# ESP32-C3 register map
Vendor: ESPRESSIF SYSTEMS (SHANGHAI) CO., LTD.; Series: ESP32 C-Series; File version: 18
CPU: RV32IMC r0p0, little endian, no MPU, no FPU, 0 interrupt priority bits
Address unit: 32 bits
Registers are 32-bit, read-write, reset 0x0 unless marked. A register's access mark holds for its fields unless they carry their own. Offsets are from the block's base; [hi:lo] are bit positions; {n}, {i} and the like mark numbered series.

## TWAI0 — Two-Wire Automotive Interface
Base 0x6002B000
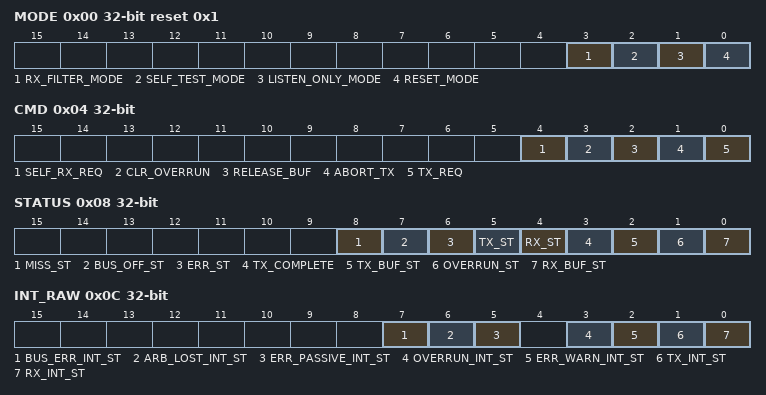
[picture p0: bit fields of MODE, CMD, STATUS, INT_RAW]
0x00 MODE reset 0x1
  [3] RX_FILTER_MODE — This bit is used to configure the filter mode. 0: Dual filter mode; 1: Single filter mode.
  [2] SELF_TEST_MODE — 1: Self test mode. In this mode the TX nodes can perform a successful transmission without receiving the acknowledge signal. This mode is often used to test a single node with the self reception request command.
  [1] LISTEN_ONLY_MODE — 1: Listen only mode. In this mode the nodes will only receive messages from the bus, without generating the acknowledge signal nor updating the RX error counter.
  [0] RESET_MODE — This bit is used to configure the operating mode of the TWAI Controller. 1: Reset mode; 0: Operating mode.
0x04 CMD wo — Command Register
  [4] SELF_RX_REQ — Self reception request command. Set the bit to 1 to allow a message be transmitted and received simultaneously.
  [3] CLR_OVERRUN — Set the bit to 1 to clear the data overrun status bit.
  [2] RELEASE_BUF — Set the bit to 1 to release the RX buffer.
  [1] ABORT_TX — Set the bit to 1 to cancel a pending transmission request.
  [0] TX_REQ — Set the bit to 1 to allow the driving nodes start transmission.
0x08 STATUS ro
  [8] MISS_ST — This bit reflects whether the data packet in the RX FIFO is complete. 1: The current packet is missing; 0: The current packet is complete
  [7] BUS_OFF_ST — 1: In bus-off status, the TWAI Controller is no longer involved in bus activities.
  [6] ERR_ST — 1: At least one of the RX/TX error counter has reached or exceeded the value set in register TWAI_ERR_WARNING_LIMIT_REG.
  [5] TX_ST — 1: The TWAI Controller is transmitting a message to the bus.
  [4] RX_ST — 1: The TWAI Controller is receiving a message from the bus.
  [3] TX_COMPLETE — 1: The TWAI controller has successfully received a packet from the bus.
  [2] TX_BUF_ST — 1: The TX buffer is empty, the CPU may write a message into it.
  [1] OVERRUN_ST — 1: The RX FIFO is full and data overrun has occurred.
  [0] RX_BUF_ST — 1: The data in the RX buffer is not empty, with at least one received data packet.
0x0C INT_RAW ro — Interrupt Register
  [7] BUS_ERR_INT_ST — Error interrupt. If this bit is set to 1, it indicates an error is detected on the bus.
  [6] ARB_LOST_INT_ST — Arbitration lost interrupt. If this bit is set to 1, it indicates an arbitration lost interrupt is generated.
  [5] ERR_PASSIVE_INT_ST — Error passive interrupt. If this bit is set to 1, it indicates the TWAI Controller is switched between error active status and error passive status due to the change of error counters.
  [3] OVERRUN_INT_ST — Data overrun interrupt. If this bit is set to 1, it indicates a data overrun interrupt is generated in the RX FIFO.
  [2] ERR_WARN_INT_ST — Error warning interrupt. If this bit is set to 1, it indicates the error status signal and the bus-off status signal of Status register have changed (e.g., switched from 0 to 1 or from 1 to 0).
  [1] TX_INT_ST — Transmit interrupt. If this bit is set to 1, it indicates the message transmitting mis- sion is finished and a new transmission is able to execute.
  [0] RX_INT_ST — Receive interrupt. If this bit is set to 1, it indicates there are messages to be handled in the RX FIFO.
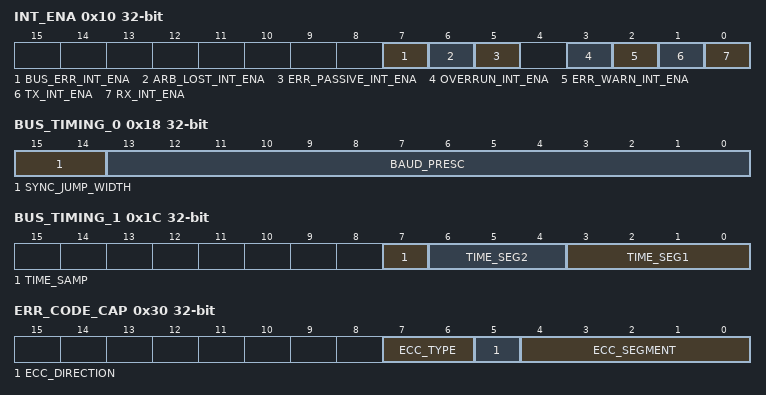
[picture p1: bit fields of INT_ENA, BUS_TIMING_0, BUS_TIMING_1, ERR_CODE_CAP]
0x10 INT_ENA — Interrupt Enable Register
  [7] BUS_ERR_INT_ENA — Set this bit to 1 to enable error interrupt.
  [6] ARB_LOST_INT_ENA — Set this bit to 1 to enable arbitration lost interrupt.
  [5] ERR_PASSIVE_INT_ENA — Set this bit to 1 to enable error passive interrupt.
  [3] OVERRUN_INT_ENA — Set this bit to 1 to enable data overrun interrupt.
  [2] ERR_WARN_INT_ENA — Set this bit to 1 to enable error warning interrupt.
  [1] TX_INT_ENA — Set this bit to 1 to enable transmit interrupt.
  [0] RX_INT_ENA — Set this bit to 1 to enable receive interrupt.
0x18 BUS_TIMING_0 — Bus Timing Register 0
  [15:14] SYNC_JUMP_WIDTH — Synchronization Jump Width (SJW), 1 \verb+~+ 14 Tq wide.
  [13:0] BAUD_PRESC — Baud Rate Prescaler, determines the frequency dividing ratio.
0x1C BUS_TIMING_1 — Bus Timing Register 1
  [7] TIME_SAMP — The number of sample points. 0: the bus is sampled once; 1: the bus is sampled three times
  [6:4] TIME_SEG2 — The width of PBS2.
  [3:0] TIME_SEG1 — The width of PBS1.
0x2C ARB_LOST_CAP ro — Arbitration Lost Capture Register
  [4:0] ARB_LOST_CAP — This register contains information about the bit position of lost arbitration.
0x30 ERR_CODE_CAP ro — Error Code Capture Register
  [7:6] ECC_TYPE — This register contains information about error types: 00: bit error; 01: form error; 10: stuff error; 11: other type of error
  [5] ECC_DIRECTION — This register contains information about transmission direction of the node when error occurs. 1: Error occurs when receiving a message; 0: Error occurs when transmitting a message
  [4:0] ECC_SEGMENT — This register contains information about the location of errors, see Table 181 for details.
0x34 ERR_WARNING_LIMIT reset 0x60 — Error Warning Limit Register
  [7:0] ERR_WARNING_LIMIT — Error warning threshold. In the case when any of a error counter value exceeds the threshold, or all the error counter values are below the threshold, an error warning interrupt will be triggered (given the enable signal is valid).
0x38 RX_ERR_CNT — Receive Error Counter Register
  [7:0] RX_ERR_CNT — The RX error counter register, reflects value changes under reception status.
0x3C TX_ERR_CNT — Transmit Error Counter Register
  [7:0] TX_ERR_CNT — The TX error counter register, reflects value changes under transmission status.
0x40 DATA_0 — Data register 0
  [7:0] TX_BYTE_0 — In reset mode, it is acceptance code register 0 with R/W Permission. In operation mode, it stores the 0th byte of the data to be transmitted or received. In operation mode, writing writes to the transmit buffer while reading reads from the receive buffer.
0x44 DATA_1 — Data register 1
  [7:0] TX_BYTE_1 — In reset mode, it is acceptance code register 1 with R/W Permission. In operation mode, it stores the 1st byte of the data to be transmitted or received. In operation mode, writing writes to the transmit buffer while reading reads from the receive buffer.
0x48 DATA_2 — Data register 2
  [7:0] TX_BYTE_2 — In reset mode, it is acceptance code register 2 with R/W Permission. In operation mode, it stores the 2nd byte of the data to be transmitted or received. In operation mode, writing writes to the transmit buffer while reading reads from the receive buffer.
0x4C DATA_3 — Data register 3
  [7:0] TX_BYTE_3 — In reset mode, it is acceptance code register 3 with R/W Permission. In operation mode, it stores the 3rd byte of the data to be transmitted or received. In operation mode, writing writes to the transmit buffer while reading reads from the receive buffer.
{0x40+4i} DATA_{i} (i=4..7) — Data register {i}
  [7:0] TX_BYTE_{i} — In reset mode, it is acceptance code register {i} with R/W Permission. In operation mode, it stores the {i}th byte of the data to be transmitted or received. In operation mode, writing writes to the transmit buffer while reading reads from the receive buffer.
{0x40+4i} DATA_{i} (i=8..12) — Data register {i}
  [7:0] TX_BYTE_{i} — In operation mode, it stores the {i}th byte of the data to be transmitted or received. In operation mode, writing writes to the transmit buffer while reading reads from the receive buffer.
0x74 RX_MESSAGE_CNT ro — Receive Message Counter Register
  [6:0] RX_MESSAGE_COUNTER — This register reflects the number of messages available within the RX FIFO.
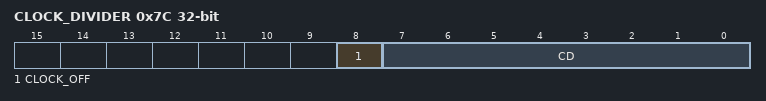
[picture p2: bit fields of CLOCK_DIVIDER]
0x7C CLOCK_DIVIDER
  [8] CLOCK_OFF — This bit can be configured under reset mode. 1: Disable the external CLKOUT pin; 0: Enable the external CLKOUT pin
  [7:0] CD — These bits are used to configure frequency dividing coefficients of the external CLKOUT pin.
